AUTOSAR XML (schema 00049)
package /Tier1/ARPlatform1/Pcpt_CMscD  # Modeling show case for arrays of axes and mapes.
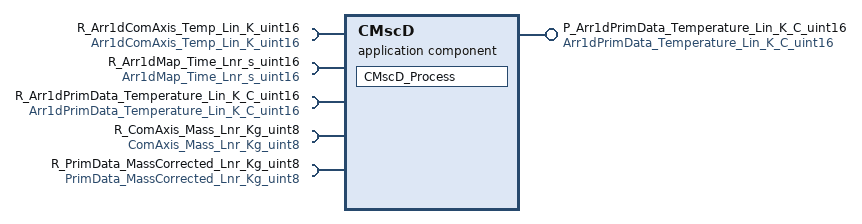
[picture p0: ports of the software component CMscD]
  application sw component type CMscD  # Modeling show case for arrays of axes and mapes.
    provide port P_Arr1dPrimData_Temperature_Lin_K_C_uint16: nonqueued-sender-com-spec{data-element=Arr1dPrimData_Temperature_Lin_K_C_uint16, init-value=[0 K, 0 K, 0 K, 0 K]}, provided-interface=Arr1dPrimData_Temperature_Lin_K_C_uint16  # Temperature 1 in Kelvin but displayed as degree Celsius
    5 x require port:
      R_Arr1dComAxis_Temp_Lin_K_uint16: required-interface=Arr1dComAxis_Temp_Lin_K_uint16  # Array of shared axis for temperature
      R_Arr1dMap_Time_Lnr_s_uint16: required-interface=Arr1dMap_Time_Lnr_s_uint16  # Map to get time dependent on temperature and mass.
      R_Arr1dPrimData_Temperature_Lin_K_C_uint16: required-interface=Arr1dPrimData_Temperature_Lin_K_C_uint16  # Temperature 1 in Kelvin but displayed as degree Celsius
      R_ComAxis_Mass_Lnr_Kg_uint8: required-interface=ComAxis_Mass_Lnr_Kg_uint8  # Shared axis for mass
      R_PrimData_MassCorrected_Lnr_Kg_uint8: required-interface=PrimData_MassCorrected_Lnr_Kg_uint8  # Primitve data for the corrected mass in kg.
    behavior CMscD: constant-value-mapping=CMscD_DefaultConstantMapping, data-type-mapping=DefaultDataTypeMapping, handle-termination-and-restart=NO-SUPPORT, included-data-type-set{data-type=TxWheelNames, literal-prefix=TxWheelNames_}
      instantiation-data-def-propss:
        {parameter-instance=R_Arr1dComAxis_Temp_Lin_K_uint16.Arr1dComAxis_Temp_Lin_K_uint16, sw-calprm-axis-set={sw-axis-index=1, sw-axis-individual=sw-variable=R_Arr1dPrimData_Temperature_Lin_K_C_uint16.Arr1dPrimData_Temperature_Lin_K_C_uint16}}
        {parameter-instance=R_Arr1dMap_Time_Lnr_s_uint16.Arr1dMap_Time_Lnr_s_uint16, sw-calprm-axis-set=[{sw-axis-index=1, sw-axis-grouped=ar-parameter=R_Arr1dComAxis_Temp_Lin_K_uint16.Arr1dComAxis_Temp_Lin_K_uint16}, {sw-axis-index=2, sw-axis-grouped=ar-parameter=R_ComAxis_Mass_Lnr_Kg_uint8.ComAxis_Mass_Lnr_Kg_uint8}]}
        {parameter-instance=R_ComAxis_Mass_Lnr_Kg_uint8.ComAxis_Mass_Lnr_Kg_uint8, sw-calprm-axis-set={sw-axis-index=1, sw-axis-individual=sw-variable=R_PrimData_MassCorrected_Lnr_Kg_uint8.PrimData_MassCorrected_Lnr_Kg_uint8}}
      runnable CMscD_Process: sw-addr-method=CODE_10MS
        data-read-access:
          access R_Arr1dPrimData_Temperature_Lin_K_C_uint16_Arr1dPrimData_Temperature_Lin_K_C_uint16: accessed-variable=R_Arr1dPrimData_Temperature_Lin_K_C_uint16.Arr1dPrimData_Temperature_Lin_K_C_uint16
          access R_PrimData_MassCorrected_Lnr_Kg_uint8_PrimData_MassCorrected_Lnr_Kg_uint8: accessed-variable=R_PrimData_MassCorrected_Lnr_Kg_uint8.PrimData_MassCorrected_Lnr_Kg_uint8
        data-write-access:
          access P_Arr1dPrimData_Temperature_Lin_K_C_uint16_Arr1dPrimData_Temperature_Lin_K_C_uint16: accessed-variable=P_Arr1dPrimData_Temperature_Lin_K_C_uint16.Arr1dPrimData_Temperature_Lin_K_C_uint16
        parameter access R_Arr1dComAxis_Temp_Lin_K_uint16_Arr1dComAxis_Temp_Lin_K_uint16: accessed-parameter=R_Arr1dComAxis_Temp_Lin_K_uint16.Arr1dComAxis_Temp_Lin_K_uint16
        parameter access R_Arr1dMap_Time_Lnr_s_uint16_Arr1dMap_Time_Lnr_s_uint16: accessed-parameter=R_Arr1dMap_Time_Lnr_s_uint16.Arr1dMap_Time_Lnr_s_uint16
        parameter access R_ComAxis_Mass_Lnr_Kg_uint8_ComAxis_Mass_Lnr_Kg_uint8: accessed-parameter=R_ComAxis_Mass_Lnr_Kg_uint8.ComAxis_Mass_Lnr_Kg_uint8
      variation point proxy ScNoOfWheels: value-access=numerical-value-variation-point=ScNoOfWheels
  constant specification mapping set CMscD_DefaultConstantMapping
    mappings:
      appl-constant=CMscD_par_P_Arr1dComAxis_Temp_Lin_K_uint16_Phys, impl-constant=CMscD_par_P_Arr1dComAxis_Temp_Lin_K_uint16_Impl
      appl-constant=CMscD_par_P_Arr1dMap_Time_Lnr_s_uint16_Phys, impl-constant=CMscD_par_P_Arr1dMap_Time_Lnr_s_uint16_Impl
  swc implementation CMscD_impl: programming-language=C, vendor-id=8, behavior=CMscD
    code-descriptors:
      code CMscD: artifact-descriptors=autosar-engineering-object={short-label=CMscD, category=SWSRC, domain=ARPlatform1}
    resource consumption CMscD_rc
      memory section CODE_10MS: sw-addrmethod=CODE_10MS
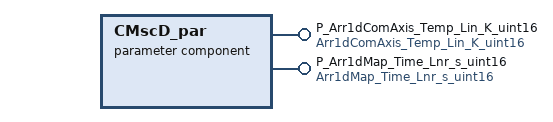
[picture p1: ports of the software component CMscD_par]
  parameter sw component type CMscD_par: constant-mapping=CMscD_DefaultConstantMapping, data-type-mapping=DefaultDataTypeMapping  # Modeling show case for arrays of axes and mapes.
    provide port P_Arr1dComAxis_Temp_Lin_K_uint16: parameter-provide-com-spec{init-value=constant-reference=CMscD_par_P_Arr1dComAxis_Temp_Lin_K_uint16_Phys, parameter=Arr1dComAxis_Temp_Lin_K_uint16}, provided-interface=Arr1dComAxis_Temp_Lin_K_uint16  # Array of shared axis for temperature
    provide port P_Arr1dMap_Time_Lnr_s_uint16: parameter-provide-com-spec{init-value=constant-reference=CMscD_par_P_Arr1dMap_Time_Lnr_s_uint16_Phys, parameter=Arr1dMap_Time_Lnr_s_uint16}, provided-interface=Arr1dMap_Time_Lnr_s_uint16  # Map to get time dependent on temperature and mass.
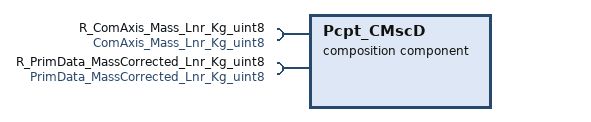
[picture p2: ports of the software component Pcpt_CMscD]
  composition sw component type Pcpt_CMscD: data-type-mapping=DefaultDataTypeMapping  # Modeling show case for arrays of axes and mapes.
    require port R_ComAxis_Mass_Lnr_Kg_uint8: required-interface=ComAxis_Mass_Lnr_Kg_uint8  # Shared axis for mass
    require port R_PrimData_MassCorrected_Lnr_Kg_uint8: required-interface=PrimData_MassCorrected_Lnr_Kg_uint8  # Primitve data for the corrected mass in kg.
    component CMscD: type=CMscD
    component CMscD_par: type=CMscD_par
    connect CMscD.P_Arr1dPrimData_Temperature_Lin_K_C_uint16 -> CMscD.R_Arr1dPrimData_Temperature_Lin_K_C_uint16
    connect CMscD_par.P_Arr1dComAxis_Temp_Lin_K_uint16 -> CMscD.R_Arr1dComAxis_Temp_Lin_K_uint16
    connect CMscD_par.P_Arr1dMap_Time_Lnr_s_uint16 -> CMscD.R_Arr1dMap_Time_Lnr_s_uint16
    delegate CMscD.R_ComAxis_Mass_Lnr_Kg_uint8 <-> outer port Pcpt_CMscD/R_ComAxis_Mass_Lnr_Kg_uint8
    delegate CMscD.R_PrimData_MassCorrected_Lnr_Kg_uint8 <-> outer port Pcpt_CMscD/R_PrimData_MassCorrected_Lnr_Kg_uint8
package /Tier1/ARPlatform1/Pcpt_CMscD/ConstantSpecifications
  4 x constant specification:
    CMscD_par_P_Arr1dComAxis_Temp_Lin_K_uint16_Impl: value-spec=[[6, 0, 0, 0, 0, 0, 0], [6, 0, 0, 0, 0, 0, 0], [6, 0, 0, 0, 0, 0, 0], [6, 0, 0, 0, 0, 0, 0]]
    CMscD_par_P_Arr1dComAxis_Temp_Lin_K_uint16_Phys: value-spec=[[0 0 0 0 0 0] K, [0 0 0 0 0 0] K, [0 0 0 0 0 0] K, [0 0 0 0 0 0] K]
    CMscD_par_P_Arr1dMap_Time_Lnr_s_uint16_Impl: value-spec=[6 x [0, 0, 0, 0], 6 x [0, 0, 0, 0], 6 x [0, 0, 0, 0], 6 x [0, 0, 0, 0]]
    CMscD_par_P_Arr1dMap_Time_Lnr_s_uint16_Phys: value-spec=[24 x 0 s size 6x4, 24 x 0 s size 6x4, 24 x 0 s size 6x4, 24 x 0 s size 6x4]
